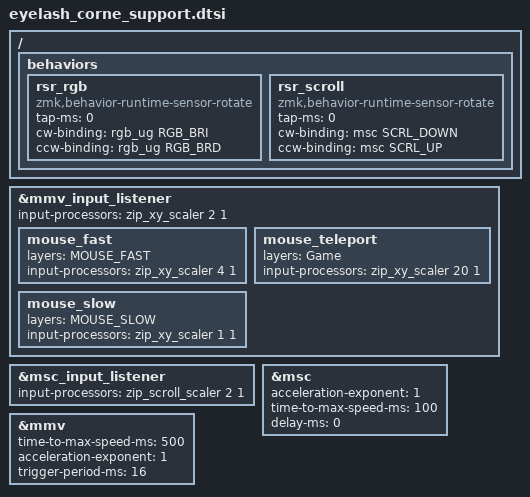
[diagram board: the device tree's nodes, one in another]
/*
 * Eyelash Corne build-only support.
 * Kept outside the graphical editor's behavior block: these are DYA-specific
 * runtime sensor definitions and pointing-listener settings, not key bindings.
 * Included by eyelash_corne.keymap; do not delete this file.
 */

#include <input/processors.dtsi>
#include <zephyr/dt-bindings/input/input-event-codes.h>
#include <behaviors/runtime-sensor-rotate.dtsi>

#define MOUSE_FAST 7
#define MOUSE_SLOW 8
#define Game 9

&mmv_input_listener {
    input-processors = <&zip_xy_scaler 2 1>;

    mouse_fast {
        layers = <MOUSE_FAST>;
        input-processors = <&zip_xy_scaler 4 1>;
    };

    mouse_teleport {
        layers = <Game>;
        input-processors = <&zip_xy_scaler 20 1>;
    };

    mouse_slow {
        layers = <MOUSE_SLOW>;
        input-processors = <&zip_xy_scaler 1 1>;
    };
};

&msc_input_listener { input-processors = <&zip_scroll_scaler 2 1>; };

&msc {
    acceleration-exponent = <1>;
    time-to-max-speed-ms = <100>;
    delay-ms = <0>;
};

&mmv {
    time-to-max-speed-ms = <500>;
    acceleration-exponent = <1>;
    trigger-period-ms = <16>;
};

/ {
    behaviors {
        /* 최신 저장소 문법에 맞춘 인코더 (옵션, 안 써도 빌드 됨) */

        rsr_rgb: rsr_rgb {
            compatible = "zmk,behavior-runtime-sensor-rotate";
            #sensor-binding-cells = <0>;
            tap-ms = <0>;
            cw-binding = <&rgb_ug RGB_BRI>;
            ccw-binding = <&rgb_ug RGB_BRD>;
        };

        rsr_scroll: rsr_scroll {
            compatible = "zmk,behavior-runtime-sensor-rotate";
            #sensor-binding-cells = <0>;
            tap-ms = <0>;
            cw-binding = <&msc SCRL_DOWN>;
            ccw-binding = <&msc SCRL_UP>;
        };
    };
};
